# STM32G474xx register map
File version: 1.0
Registers are 32-bit, read-write, reset 0x0 unless marked. A register's access mark holds for its fields unless they carry their own. Offsets are from the block's base; [hi:lo] are bit positions; lines under a group give offsets from that group; {n}, {i} and the like mark numbered series; 'fields as' and 'values as' point back to an identical list.

## ADC12_COMMON
Base 0x50000300
Same registers: ADC345_COMMON 0x50000700
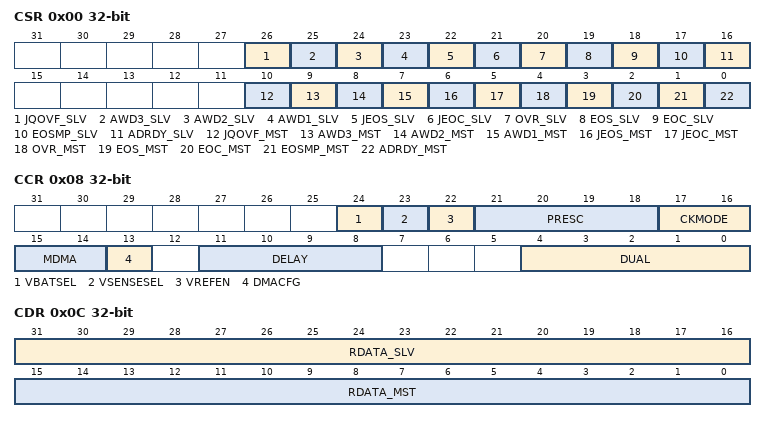
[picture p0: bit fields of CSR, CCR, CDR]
0x00 CSR — ADC common status register
  [26] JQOVF_SLV — ADC multimode slave group injected contexts queue overflow flag
  [25] AWD3_SLV — ADC multimode slave analog watchdog 3 flag
  [24] AWD2_SLV — ADC multimode slave analog watchdog 2 flag
  [23] AWD1_SLV — ADC multimode slave analog watchdog 1 flag
  [22] JEOS_SLV — ADC multimode slave group injected end of sequence conversions flag
  [21] JEOC_SLV — ADC multimode slave group injected end of unitary conversion flag
  [20] OVR_SLV — ADC multimode slave group regular overrun flag
  [19] EOS_SLV — ADC multimode slave group regular end of sequence conversions flag
  [18] EOC_SLV — ADC multimode slave group regular end of unitary conversion flag
  [17] EOSMP_SLV — ADC multimode slave group regular end of sampling flag
  [16] ADRDY_SLV — ADC multimode slave ready flag
  [10] JQOVF_MST — ADC multimode master group injected contexts queue overflow flag
  [9] AWD3_MST — ADC multimode master analog watchdog 3 flag
  [8] AWD2_MST — ADC multimode master analog watchdog 2 flag
  [7] AWD1_MST — ADC multimode master analog watchdog 1 flag
  [6] JEOS_MST — ADC multimode master group injected end of sequence conversions flag
  [5] JEOC_MST — ADC multimode master group injected end of unitary conversion flag
  [4] OVR_MST — ADC multimode master group regular overrun flag
  [3] EOS_MST — ADC multimode master group regular end of sequence conversions flag
  [2] EOC_MST — ADC multimode master group regular end of unitary conversion flag
  [1] EOSMP_MST — ADC multimode master group regular end of sampling flag
  [0] ADRDY_MST — ADC multimode master ready flag
0x08 CCR — ADC common configuration register
  [24] VBATSEL — ADC internal path to battery voltage enable
  [23] VSENSESEL — ADC internal path to temperature sensor enable
  [22] VREFEN — ADC internal path to VrefInt enable
  [21:18] PRESC — ADC common clock prescaler, only for clock source asynchronous
  [17:16] CKMODE — ADC common clock source and prescaler (prescaler only for clock source synchronous)
  [15:14] MDMA — ADC multimode DMA transfer enable
  [13] DMACFG — ADC multimode DMA transfer configuration
  [11:8] DELAY — ADC multimode delay between 2 sampling phases
    0=DELAY_1CYCLE; {v}=DELAY_{v+1}CYCLES (v=1..11)
  [4:0] DUAL — ADC multimode mode selection
    0=INDEPENDENT; 6=DUAL_REG_SIMULT; 7=DUAL_REG_INTERL; 5=DUAL_INJ_SIMULT; 9=DUAL_INJ_ALTERN; 1=DUAL_REG_SIM_INJ_SIM; 2=DUAL_REG_SIM_INJ_ALT; 3=DUAL_REG_INT_INJ_SIM
0x0C CDR — ADC common group regular data register
  [31:16] RDATA_SLV — ADC multimode slave group regular conversion data
  [15:0] RDATA_MST — ADC multimode master group regular conversion data

## RNG
Base 0x50060800
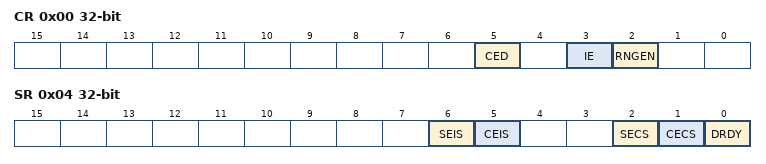
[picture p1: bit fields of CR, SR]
0x00 CR — RNG control register
  [5] CED, [3] IE, [2] RNGEN
0x04 SR — RNG status register
  [6] SEIS, [5] CEIS, [2] SECS, [1] CECS, [0] DRDY
0x08 DR — RNG data register

## FMC_Bank1_R — Flexible Memory Controller
Base 0xA0000000
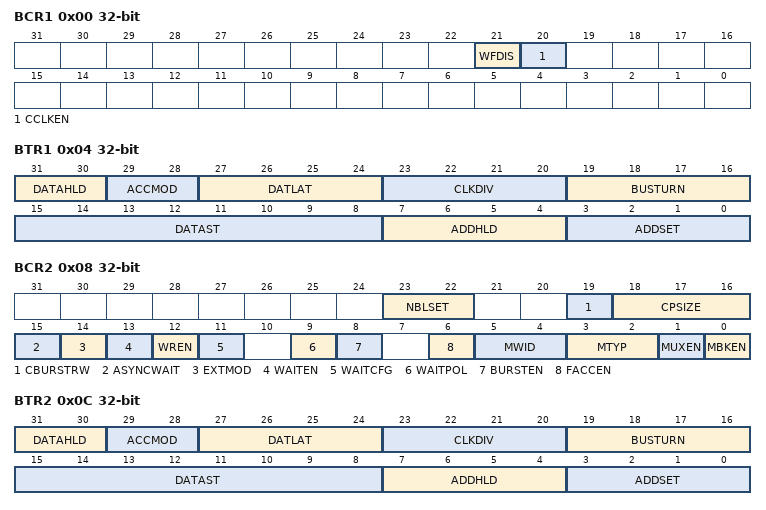
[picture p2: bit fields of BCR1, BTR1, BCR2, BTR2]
0x00 BCR1 — NOR/PSRAM chip-select control register(BCR) and chip-select timing register(BTR)
  [21] WFDIS — Write FIFO Disable
  [20] CCLKEN — Continuous clock enable
0x04 BTR1 — NOR/PSRAM chip-select control register(BCR) and chip-select timing register(BTR)
  [31:30] DATAHLD — DATAHLD[1:0] bits (Data hold phase duration)
  [29:28] ACCMOD — ACCMOD[1:0] bits (Access mode)
  [27:24] DATLAT — DATLAT[3:0] bits (Data latency)
  [23:20] CLKDIV — CLKDIV[3:0] bits (Clock divide ratio)
  [19:16] BUSTURN — BUSTURN[3:0] bits (Bus turnaround phase duration)
  [15:8] DATAST — DATAST [3:0] bits (Data-phase duration)
  [7:4] ADDHLD — ADDHLD[3:0] bits (Address-hold phase duration)
  [3:0] ADDSET — ADDSET[3:0] bits (Address setup phase duration)
0x08 BCR2 — NOR/PSRAM chip-select control register(BCR) and chip-select timing register(BTR)
  [23:22] NBLSET — Byte lane (NBL) setup
  [19] CBURSTRW — Write burst enable
  [18:16] CPSIZE — CRAM page size
  [15] ASYNCWAIT — Asynchronous wait
  [14] EXTMOD — Extended mode enable
  [13] WAITEN — Wait enable bit
  [12] WREN — Write enable bit
  [11] WAITCFG — Wait timing configuration
  [9] WAITPOL — Wait signal polarity bit
  [8] BURSTEN — Burst enable bit
  [6] FACCEN — Flash access enable
  [5:4] MWID — MWID[1:0] bits (Memory data bus width)
  [3:2] MTYP — MTYP[1:0] bits (Memory type)
  [1] MUXEN — Address/data multiplexing enable bit
  [0] MBKEN — Memory bank enable bit
0x0C BTR2 — NOR/PSRAM chip-select control register(BCR) and chip-select timing register(BTR)
  fields as BTR1
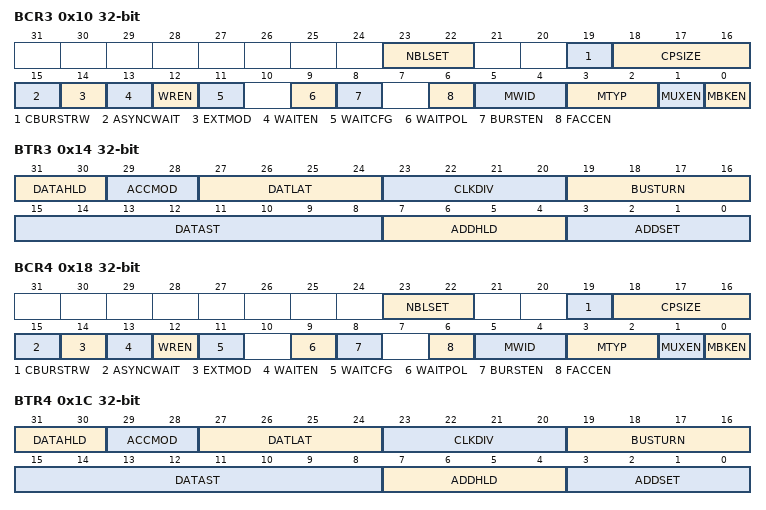
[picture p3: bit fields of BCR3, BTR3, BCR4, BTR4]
0x10 BCR3 — NOR/PSRAM chip-select control register(BCR) and chip-select timing register(BTR)
  fields as BCR2
0x14 BTR3 — NOR/PSRAM chip-select control register(BCR) and chip-select timing register(BTR)
  fields as BTR1
0x18 BCR4 — NOR/PSRAM chip-select control register(BCR) and chip-select timing register(BTR)
  fields as BCR2
0x1C BTR4 — NOR/PSRAM chip-select control register(BCR) and chip-select timing register(BTR)
  fields as BTR1
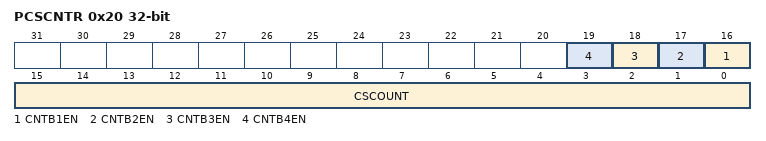
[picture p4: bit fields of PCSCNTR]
0x20 PCSCNTR — PSRAM chip-select counter register
  [n+15] CNTB{n}EN (n=1..4) — Counter PSRAM/NOR Bank1_{n} enable
  [15:0] CSCOUNT — CSCOUNT[15:0] bits (Chip select counter)
